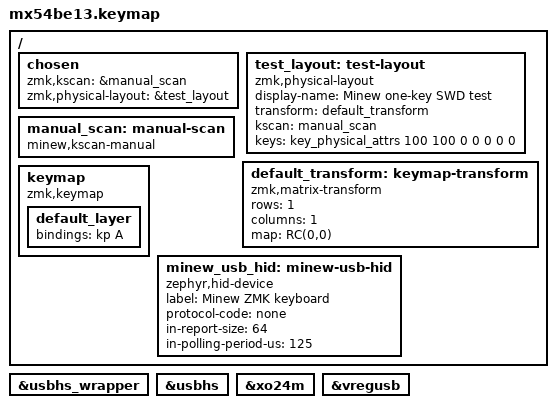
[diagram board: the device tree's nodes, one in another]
#include <behaviors.dtsi>
#include <dt-bindings/zmk/keys.h>
#include <dt-bindings/zmk/matrix_transform.h>
#include <physical_layouts.dtsi>
/ {
 chosen { zmk,kscan = &manual_scan; zmk,physical-layout = &test_layout; };
 test_layout: test-layout {
  compatible = "zmk,physical-layout";
  display-name = "Minew one-key SWD test";
  transform = <&default_transform>;
  kscan = <&manual_scan>;
  keys = <&key_physical_attrs 100 100 0 0 0 0 0>;
 };
 manual_scan: manual-scan { compatible = "minew,kscan-manual"; };
 default_transform: keymap-transform {
  compatible = "zmk,matrix-transform";
  rows = <1>; columns = <1>;
  map = <RC(0,0)>;
 };
 keymap {
  compatible = "zmk,keymap";
  default_layer { bindings = <&kp A>; };
 };
};

&usbhs_wrapper { status = "okay"; };
zephyr_udc0: &usbhs { status = "okay"; };
&xo24m { status = "okay"; };
&vregusb { status = "okay"; };
/ {
 minew_usb_hid: minew-usb-hid {
  compatible = "zephyr,hid-device";
  label = "Minew ZMK keyboard";
  protocol-code = "none";
  in-report-size = <64>;
  in-polling-period-us = <125>;
 };
};
